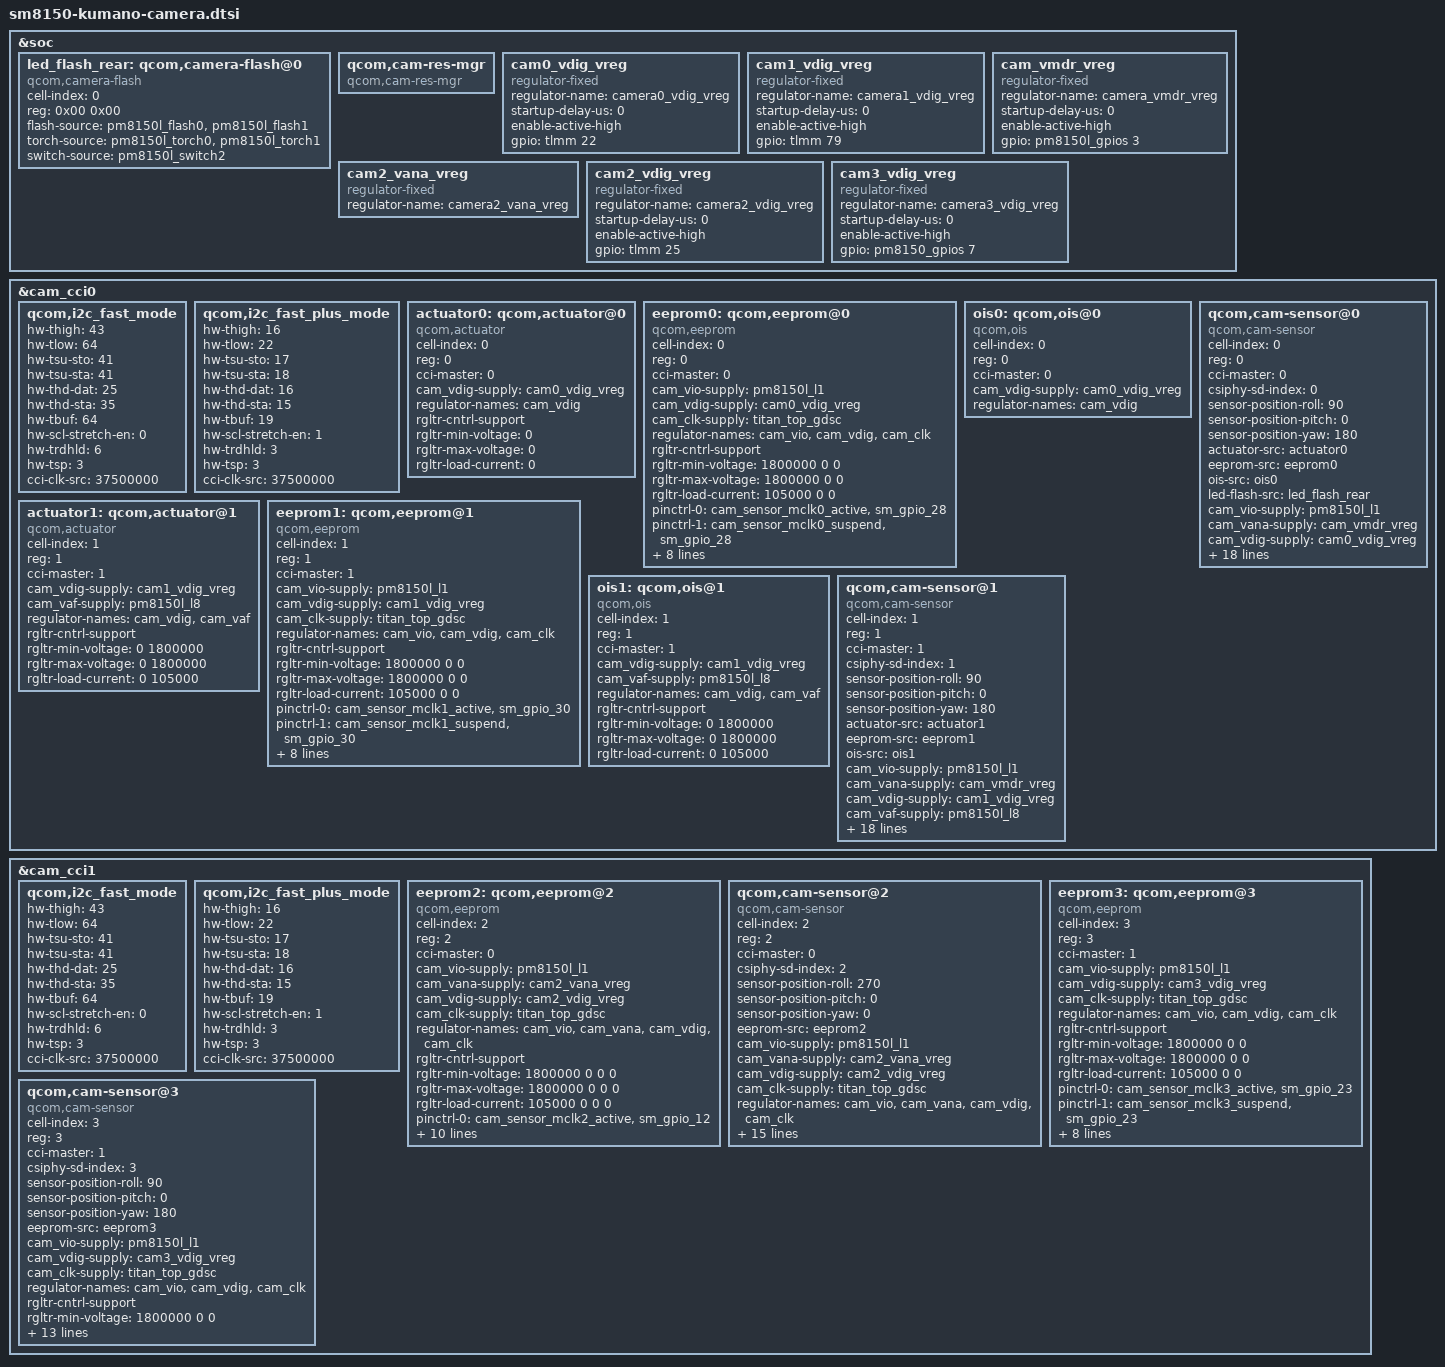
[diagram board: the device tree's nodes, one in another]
#include <dt-bindings/clock/qcom,camcc-sm8150.h>

&soc {
	#address-cells = <1>;
	#size-cells = <1>;

	led_flash_rear: qcom,camera-flash@0 {
		cell-index = <0>;
		reg = <0x00 0x00>;
		compatible = "qcom,camera-flash";
		flash-source = <&pm8150l_flash0 &pm8150l_flash1>;
		torch-source = <&pm8150l_torch0 &pm8150l_torch1>;
		switch-source = <&pm8150l_switch2>;
		status = "ok";
	};

	qcom,cam-res-mgr {
		compatible = "qcom,cam-res-mgr";
		status = "ok";
	};

	cam0_vdig_vreg: cam0_vdig_vreg {
		compatible = "regulator-fixed";
		regulator-name = "camera0_vdig_vreg";
		startup-delay-us = <0>;
		enable-active-high;
		gpio = <&tlmm 22 0>;
	};

	cam1_vdig_vreg: cam1_vdig_vreg {
		compatible = "regulator-fixed";
		regulator-name = "camera1_vdig_vreg";
		startup-delay-us = <0>;
		enable-active-high;
		gpio = <&tlmm 79 0>;
	};

	cam_vmdr_vreg: cam_vmdr_vreg {
		compatible = "regulator-fixed";
		regulator-name = "camera_vmdr_vreg";
		startup-delay-us = <0>;
		enable-active-high;
		gpio = <&pm8150l_gpios 3 0>;
	};

	cam2_vana_vreg: cam2_vana_vreg {
		compatible = "regulator-fixed";
		regulator-name = "camera2_vana_vreg";
	};

	cam2_vdig_vreg: cam2_vdig_vreg {
		compatible = "regulator-fixed";
		regulator-name = "camera2_vdig_vreg";
		startup-delay-us = <0>;
		enable-active-high;
		gpio = <&tlmm 25 0>;
	};

	cam3_vdig_vreg: cam3_vdig_vreg {
		compatible = "regulator-fixed";
		regulator-name = "camera3_vdig_vreg";
		startup-delay-us = <0>;
		enable-active-high;
		gpio = <&pm8150_gpios 7 0>;
	};
};

&cam_cci0 {
	#address-cells = <1>;
	#size-cells = <0>;

	qcom,i2c_fast_mode {
		hw-thigh = <43>;
		hw-tlow = <64>;
		hw-tsu-sto = <41>;
		hw-tsu-sta = <41>;
		hw-thd-dat = <25>;
		hw-thd-sta = <35>;
		hw-tbuf = <64>;
		hw-scl-stretch-en = <0>;
		hw-trdhld = <6>;
		hw-tsp = <3>;
		cci-clk-src = <37500000>;
		status = "ok";
	};

	qcom,i2c_fast_plus_mode {
		hw-thigh = <16>;
		hw-tlow = <22>;
		hw-tsu-sto = <17>;
		hw-tsu-sta = <18>;
		hw-thd-dat = <16>;
		hw-thd-sta = <15>;
		hw-tbuf = <19>;
		hw-scl-stretch-en = <1>;
		hw-trdhld = <3>;
		hw-tsp = <3>;
		cci-clk-src = <37500000>;
		status = "ok";
	};

	actuator0: qcom,actuator@0 {
		cell-index = <0>;
		compatible = "qcom,actuator";
		reg = <0>;
		cci-master = <0>;
		cam_vdig-supply = <&cam0_vdig_vreg>;
		regulator-names = "cam_vdig";
		rgltr-cntrl-support;
		rgltr-min-voltage = <0>;
		rgltr-max-voltage = <0>;
		rgltr-load-current = <0>;
		status = "ok";
	};

	eeprom0: qcom,eeprom@0 {
		cell-index = <0>;
		compatible = "qcom,eeprom";
		reg = <0>;
		cci-master = <0>;
		cam_vio-supply = <&pm8150l_l1>;
		cam_vdig-supply = <&cam0_vdig_vreg>;
		cam_clk-supply = <&titan_top_gdsc>;
		regulator-names = "cam_vio", "cam_vdig", "cam_clk";
		rgltr-cntrl-support;
		rgltr-min-voltage = <1800000 0 0>;
		rgltr-max-voltage = <1800000 0 0>;
		rgltr-load-current = <105000 0 0>;
		pinctrl-names = "cam_default", "cam_suspend";
		pinctrl-0 = <&cam_sensor_mclk0_active &sm_gpio_28>;
		pinctrl-1 = <&cam_sensor_mclk0_suspend &sm_gpio_28>;
		gpios = <&tlmm 13 0>, <&tlmm 28 0>;
		gpio-reset = <1>;
		gpio-req-tbl-num = <0 1>;
		gpio-req-tbl-flags = <1 0>;
		gpio-req-tbl-label = "CAMIF_MCLK0", "CAMIF_RESET0";
		clocks = <&clock_camcc CAM_CC_MCLK0_CLK>;
		clock-names = "cam_clk";
		clock-cntl-level = "turbo";
		clock-rates = <24000000>;
		status = "ok";
	};

	ois0: qcom,ois@0 {
		cell-index = <0>;
		compatible = "qcom,ois";
		reg = <0>;
		cci-master = <0>;
		cam_vdig-supply = <&cam0_vdig_vreg>;
		regulator-names = "cam_vdig";
		status = "ok";
	};

	qcom,cam-sensor@0 {
		cell-index = <0>;
		compatible = "qcom,cam-sensor";
		reg = <0>;
		cci-master = <0>;
		csiphy-sd-index = <0>;
		sensor-position-roll = <90>;
		sensor-position-pitch = <0>;
		sensor-position-yaw = <180>;
		actuator-src = <&actuator0>;
		eeprom-src = <&eeprom0>;
		ois-src = <&ois0>;
		led-flash-src = <&led_flash_rear>;
		cam_vio-supply = <&pm8150l_l1>;
		cam_vana-supply = <&cam_vmdr_vreg>;
		cam_vdig-supply = <&cam0_vdig_vreg>;
		cam_clk-supply = <&titan_top_gdsc>;
		regulator-names = "cam_vio", "cam_vana", "cam_vdig", "cam_clk";
		rgltr-cntrl-support;
		rgltr-min-voltage = <1800000 0 0 0>;
		rgltr-max-voltage = <1800000 0 0 0>;
		rgltr-load-current = <105000 0 0 0>;
		pinctrl-names = "cam_default", "cam_suspend";
		pinctrl-0 = <&cam_sensor_mclk0_active &sm_gpio_28>;
		pinctrl-1 = <&cam_sensor_mclk0_suspend &sm_gpio_28>;
		gpios = <&tlmm 13 0>, <&tlmm 28 0>;
		gpio-reset = <1>;
		gpio-req-tbl-num = <0 1>;
		gpio-req-tbl-flags = <1 0>;
		gpio-req-tbl-label = "CAMIF_MCLK0", "CAMIF_RESET0";
		clocks = <&clock_camcc CAM_CC_MCLK0_CLK>;
		clock-names = "cam_clk";
		clock-cntl-level = "turbo";
		clock-rates = <24000000>;
		status = "ok";
	};

	actuator1: qcom,actuator@1 {
		cell-index = <1>;
		compatible = "qcom,actuator";
		reg = <1>;
		cci-master = <1>;
		cam_vdig-supply = <&cam1_vdig_vreg>;
		cam_vaf-supply = <&pm8150l_l8>;
		regulator-names = "cam_vdig", "cam_vaf";
		rgltr-cntrl-support;
		rgltr-min-voltage = <0 1800000>;
		rgltr-max-voltage = <0 1800000>;
		rgltr-load-current = <0 105000>;
		status = "ok";
	};

	eeprom1: qcom,eeprom@1 {
		cell-index = <1>;
		compatible = "qcom,eeprom";
		reg = <1>;
		cci-master = <1>;
		cam_vio-supply = <&pm8150l_l1>;
		cam_vdig-supply = <&cam1_vdig_vreg>;
		cam_clk-supply = <&titan_top_gdsc>;
		regulator-names = "cam_vio", "cam_vdig", "cam_clk";
		rgltr-cntrl-support;
		rgltr-min-voltage = <1800000 0 0>;
		rgltr-max-voltage = <1800000 0 0>;
		rgltr-load-current = <105000 0 0>;
		pinctrl-names = "cam_default", "cam_suspend";
		pinctrl-0 = <&cam_sensor_mclk1_active &sm_gpio_30>;
		pinctrl-1 = <&cam_sensor_mclk1_suspend &sm_gpio_30>;
		gpios = <&tlmm 14 0>, <&tlmm 30 0>;
		gpio-reset = <1>;
		gpio-req-tbl-num = <0 1>;
		gpio-req-tbl-flags = <1 0>;
		gpio-req-tbl-label = "CAMIF_MCLK1", "CAMIF_RESET1";
		clocks = <&clock_camcc CAM_CC_MCLK1_CLK>;
		clock-names = "cam_clk";
		clock-cntl-level = "turbo";
		clock-rates = <24000000>;
		status = "ok";
	};

	ois1: qcom,ois@1 {
		cell-index = <1>;
		compatible = "qcom,ois";
		reg = <1>;
		cci-master = <1>;
		cam_vdig-supply = <&cam1_vdig_vreg>;
		cam_vaf-supply = <&pm8150l_l8>;
		regulator-names = "cam_vdig", "cam_vaf";
		rgltr-cntrl-support;
		rgltr-min-voltage = <0 1800000>;
		rgltr-max-voltage = <0 1800000>;
		rgltr-load-current = <0 105000>;
		status = "ok";
	};

	qcom,cam-sensor@1 {
		cell-index = <1>;
		compatible = "qcom,cam-sensor";
		reg = <1>;
		cci-master = <1>;
		csiphy-sd-index = <1>;
		sensor-position-roll = <90>;
		sensor-position-pitch = <0>;
		sensor-position-yaw = <180>;
		actuator-src = <&actuator1>;
		eeprom-src = <&eeprom1>;
		ois-src = <&ois1>;
		cam_vio-supply = <&pm8150l_l1>;
		cam_vana-supply = <&cam_vmdr_vreg>;
		cam_vdig-supply = <&cam1_vdig_vreg>;
		cam_vaf-supply = <&pm8150l_l8>;
		cam_clk-supply = <&titan_top_gdsc>;
		regulator-names = "cam_vio", "cam_vana", "cam_vdig", "cam_vaf", "cam_clk";
		rgltr-cntrl-support;
		rgltr-min-voltage = <1800000 0 0 1800000 0>;
		rgltr-max-voltage = <1800000 0 0 1800000 0>;
		rgltr-load-current = <105000 0 0 105000 0>;
		pinctrl-names = "cam_default", "cam_suspend";
		pinctrl-0 = <&cam_sensor_mclk1_active &sm_gpio_30>;
		pinctrl-1 = <&cam_sensor_mclk1_suspend &sm_gpio_30>;
		gpios = <&tlmm 14 0>, <&tlmm 30 0>;
		gpio-reset = <1>;
		gpio-req-tbl-num = <0 1>;
		gpio-req-tbl-flags = <1 0>;
		gpio-req-tbl-label = "CAMIF_MCLK1", "CAMIF_RESET1";
		clocks = <&clock_camcc CAM_CC_MCLK1_CLK>;
		clock-names = "cam_clk";
		clock-cntl-level = "turbo";
		clock-rates = <24000000>;
		status = "ok";
	};
};

&cam_cci1 {
	#address-cells = <1>;
	#size-cells = <0>;

	qcom,i2c_fast_mode {
		hw-thigh = <43>;
		hw-tlow = <64>;
		hw-tsu-sto = <41>;
		hw-tsu-sta = <41>;
		hw-thd-dat = <25>;
		hw-thd-sta = <35>;
		hw-tbuf = <64>;
		hw-scl-stretch-en = <0>;
		hw-trdhld = <6>;
		hw-tsp = <3>;
		cci-clk-src = <37500000>;
		status = "ok";
	};

	qcom,i2c_fast_plus_mode {
		hw-thigh = <16>;
		hw-tlow = <22>;
		hw-tsu-sto = <17>;
		hw-tsu-sta = <18>;
		hw-thd-dat = <16>;
		hw-thd-sta = <15>;
		hw-tbuf = <19>;
		hw-scl-stretch-en = <1>;
		hw-trdhld = <3>;
		hw-tsp = <3>;
		cci-clk-src = <37500000>;
		status = "ok";
	};

	eeprom2: qcom,eeprom@2 {
		cell-index = <2>;
		compatible = "qcom,eeprom";
		reg = <2>;
		cci-master = <0>;
		cam_vio-supply = <&pm8150l_l1>;
		cam_vana-supply = <&cam2_vana_vreg>;
		cam_vdig-supply = <&cam2_vdig_vreg>;
		cam_clk-supply = <&titan_top_gdsc>;
		regulator-names = "cam_vio", "cam_vana", "cam_vdig", "cam_clk";
		rgltr-cntrl-support;
		rgltr-min-voltage = <1800000 0 0 0>;
		rgltr-max-voltage = <1800000 0 0 0>;
		rgltr-load-current = <105000 0 0 0>;
		pinctrl-names = "cam_default", "cam_suspend";
		pinctrl-0 = <&cam_sensor_mclk2_active &sm_gpio_12>;
		pinctrl-1 = <&cam_sensor_mclk2_suspend &sm_gpio_12>;
		gpios = <&tlmm 15 0>, <&tlmm 12 0>;
		gpio-reset = <1>;
		gpio-req-tbl-num = <0 1>;
		gpio-req-tbl-flags = <1 0>;
		gpio-req-tbl-label = "CAMIF_MCLK2", "CAMIF_RESET2";
		clocks = <&clock_camcc CAM_CC_MCLK2_CLK>;
		clock-names = "cam_clk";
		clock-cntl-level = "turbo";
		clock-rates = <24000000>;
		status = "ok";
	};

	qcom,cam-sensor@2 {
		cell-index = <2>;
		compatible = "qcom,cam-sensor";
		reg = <2>;
		cci-master = <0>;
		csiphy-sd-index = <2>;
		sensor-position-roll = <270>;
		sensor-position-pitch = <0>;
		sensor-position-yaw = <0>;
		eeprom-src = <&eeprom2>;
		cam_vio-supply = <&pm8150l_l1>;
		cam_vana-supply = <&cam2_vana_vreg>;
		cam_vdig-supply = <&cam2_vdig_vreg>;
		cam_clk-supply = <&titan_top_gdsc>;
		regulator-names = "cam_vio", "cam_vana", "cam_vdig", "cam_clk";
		rgltr-cntrl-support;
		rgltr-min-voltage = <1800000 0 0 0>;
		rgltr-max-voltage = <1800000 0 0 0>;
		rgltr-load-current = <105000 0 0 0>;
		pinctrl-names = "cam_default", "cam_suspend";
		pinctrl-0 = <&cam_sensor_mclk2_active &sm_gpio_12>;
		pinctrl-1 = <&cam_sensor_mclk2_suspend &sm_gpio_12>;
		gpios = <&tlmm 15 0>, <&tlmm 12 0>;
		gpio-reset = <1>;
		gpio-req-tbl-num = <0 1>;
		gpio-req-tbl-flags = <1 0>;
		gpio-req-tbl-label = "CAMIF_MCLK2", "CAMIF_RESET2";
		clocks = <&clock_camcc CAM_CC_MCLK2_CLK>;
		clock-names = "cam_clk";
		clock-cntl-level = "turbo";
		clock-rates = <24000000>;
		status = "ok";
	};

	eeprom3: qcom,eeprom@3 {
		cell-index = <3>;
		compatible = "qcom,eeprom";
		reg = <3>;
		cci-master = <1>;
		cam_vio-supply = <&pm8150l_l1>;
		cam_vdig-supply = <&cam3_vdig_vreg>;
		cam_clk-supply = <&titan_top_gdsc>;
		regulator-names = "cam_vio", "cam_vdig", "cam_clk";
		rgltr-cntrl-support;
		rgltr-min-voltage = <1800000 0 0>;
		rgltr-max-voltage = <1800000 0 0>;
		rgltr-load-current = <105000 0 0>;
		pinctrl-names = "cam_default", "cam_suspend";
		pinctrl-0 = <&cam_sensor_mclk3_active &sm_gpio_23>;
		pinctrl-1 = <&cam_sensor_mclk3_suspend &sm_gpio_23>;
		gpios = <&tlmm 16 0>, <&tlmm 23 0>;
		gpio-reset = <1>;
		gpio-req-tbl-num = <0 1>;
		gpio-req-tbl-flags = <1 0>;
		gpio-req-tbl-label = "CAMIF_MCLK3", "CAMIF_RESET3";
		clocks = <&clock_camcc CAM_CC_MCLK3_CLK>;
		clock-names = "cam_clk";
		clock-cntl-level = "turbo";
		clock-rates = <24000000>;
		status = "ok";
	};

	qcom,cam-sensor@3 {
		cell-index = <3>;
		compatible = "qcom,cam-sensor";
		reg = <3>;
		cci-master = <1>;
		csiphy-sd-index = <3>;
		sensor-position-roll = <90>;
		sensor-position-pitch = <0>;
		sensor-position-yaw = <180>;
		eeprom-src = <&eeprom3>;
		cam_vio-supply = <&pm8150l_l1>;
		cam_vdig-supply = <&cam3_vdig_vreg>;
		cam_clk-supply = <&titan_top_gdsc>;
		regulator-names = "cam_vio", "cam_vdig", "cam_clk";
		rgltr-cntrl-support;
		rgltr-min-voltage = <1800000 0 0>;
		rgltr-max-voltage = <1800000 0 0>;
		rgltr-load-current = <105000 0 0>;
		pinctrl-names = "cam_default", "cam_suspend";
		pinctrl-0 = <&cam_sensor_mclk3_active &sm_gpio_23>;
		pinctrl-1 = <&cam_sensor_mclk3_suspend &sm_gpio_23>;
		gpios = <&tlmm 16 0>, <&tlmm 23 0>;
		gpio-reset = <1>;
		gpio-req-tbl-num = <0 1>;
		gpio-req-tbl-flags = <1 0>;
		gpio-req-tbl-label = "CAMIF_MCLK3", "CAMIF_RESET3";
		clocks = <&clock_camcc CAM_CC_MCLK3_CLK>;
		clock-names = "cam_clk";
		clock-cntl-level = "turbo";
		clock-rates = <24000000>;
		status = "ok";
	};
};
